# RasbperryPi register map
File version: 1
Registers are 32-bit, read-write, reset 0x0 unless marked. A register's access mark holds for its fields unless they carry their own. Offsets are from the block's base; [hi:lo] are bit positions; {n}, {i} and the like mark numbered series.

## HDMI — Derived from hdmicore.h
Base 0x7E902000
0x00 CORE_REV 16-bit
  [15:0] data
0x00 CEC_TX_DATA_2
  [31:0] data
{0x0+4i} RAM_GCP_{i} (i=0..8)
  [31:0] data
0x00 RAM_PACKET_7_1
  [31:0] data
0x04 SW_RESET_CNTRL 2-bit
  [1:0] data
0x04 CEC_TX_DATA_3
  [31:0] data
0x04 RAM_PACKET_7_2
  [31:0] data
0x08 HOTPLUG_INT 3-bit reset 0x6
  [2:0] data
0x08 CEC_TX_DATA_4
  [31:0] data
0x08 RAM_PACKET_7_3
  [31:0] data
0x0C HOTPLUG 1-bit
  [0] data
{0x8+4i} CEC_RX_DATA_{i} (i=1..4)
  [31:0] data
0x0C RAM_PACKET_7_4
  [31:0] data
0x10 BKSV0
  [31:0] data
0x10 RAM_PACKET_7_5
  [31:0] data
0x14 BKSV1
  [31:0] data
0x14 RAM_PACKET_7_6
  [31:0] data
0x18 AN0
  [31:0] data
0x18 RAM_PACKET_7_7
  [31:0] data
0x1C AN1
  [31:0] data
0x1C PACKET_FIFO_CTL 2-bit
  [1:0] data
0x1C RAM_PACKET_7_8
  [31:0] data
0x20 AN_INFLUENCE_1
  [31:0] data
0x20 PACKET_FIFO_CFG 1-bit
  [0] data
{0x20+4i} RAM_PACKET_8_{i} (i=0..8)
  [31:0] data
0x24 AN_INFLUENCE_2
  [31:0] data
0x24 PACKET_FIFO_STATUS 26-bit
  [25:0] data
{0x24+4i} RAM_PACKET_1_{i} (i=0..8)
  [31:0] data
0x28 TST_AN0
  [31:0] data
0x28 DVO_TIMING_ADJUST_A 20-bit reset 0x88
  [19:0] data
0x2C TST_AN1
  [31:0] data
0x2C DVO_TIMING_ADJUST_B reset 0x88
  [31:0] data
0x30 KSV_FIFO_0
  [31:0] data
0x30 DVO_TIMING_ADJUST_C reset 0x88
  [31:0] data
0x34 KSV_FIFO_1 8-bit
  [7:0] data
0x34 DVO_TIMING_ADJUST_D reset 0x88
  [31:0] data
0x38 V
  [31:0] data
0x38 DETECTED_HORZA 15-bit reset 0x80
  [14] MANUAL_VPOL, [13] MANUAL_HPOL, [12:0] MANUAL_HAP
0x3C HDCP_KEY_1
  [31:0] data
0x3C DETECTED_HORZB 30-bit reset 0x10
  [29:20] MANUAL_HBP, [19:10] MANUAL_HSP, [9] MANUAL_HFP, [8:0] _
0x40 HDCP_KEY_2
  [31:0] data
0x40 DETECTED_VERTA0 25-bit reset 0xE0
  [24:20] MANUAL_VSP0, [19:13] MANUAL_VFP0, [12:0] MANUAL_VAL0
0x40 CPU_STATUS
  [31:0] data
0x44 HDCP_CTL 17-bit
  [16:0] data
0x44 DETECTED_VERTB0 22-bit reset 0x21
  [21:9] MANUAL_VSPO0, [8] MANUAL_VBP0, [7:0] _
0x44 CPU_SET
  [31:0] data
{0x44+4i} RAM_PACKET_9_{i} (i=0..8)
  [31:0] data
0x48 CP_STATUS
  [31:0] data
0x48 DETECTED_VERTA1 25-bit reset 0xE0
  [24:20] MANUAL_VSP1, [19:13] MANUAL_VFP1, [12:0] MANUAL_VAL1
0x48 CPU_CLEAR
  [31:0] data
{0x48+4i} RAM_PACKET_2_{i} (i=0..8)
  [31:0] data
0x4C CP_INTEGRITY
  [31:0] data
0x4C DETECTED_VERTB1 22-bit reset 0x21
  [21:9] MANUAL_VSPO1, [8] MANUAL_VBP1, [7:0] _
0x4C CPU_MASK_STATUS reset 0xFF
  [31:0] data
0x50 CP_INTEGRITY_CFG 17-bit
  [16:0] data
0x50 13_AUDIO_CFG_1 10-bit reset 0xC8
  [9:0] data
0x50 CPU_MASK_SET reset 0xFF
  [31:0] data
0x54 CP_CONFIG 31-bit reset 0x80
  [30:0] data
0x54 13_AUDIO_STATUS_1 1-bit
  [0] data
0x54 CPU_MASK_CLEAR reset 0xFF
  [31:0] data
0x58 CP_TST 22-bit
  [21:0] data
0x58 HBR_AUDIO_PACKET_HEADER 20-bit reset 0x9
  [19:0] data
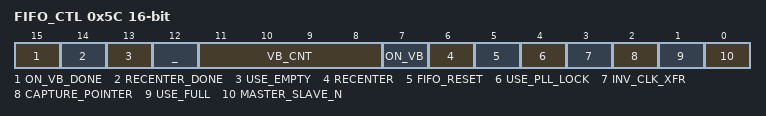
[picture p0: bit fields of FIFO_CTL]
0x5C FIFO_CTL 16-bit
  [15] ON_VB_DONE, [14] RECENTER_DONE, [13] USE_EMPTY, [12] _, [11:8] VB_CNT, [7] ON_VB, [6] RECENTER, [5] FIFO_RESET, [4] USE_PLL_LOCK, [3] INV_CLK_XFR, [2] CAPTURE_POINTER, [1] USE_FULL, [0] MASTER_SLAVE_N
0x5C POSTING_MASTER 8-bit reset 0xFF
  [7:0] data
0x60 READ_POINTERS 31-bit
  [30] DOMAIN_HALF_FULL, [29:27] DOMAIN_WR_ADDR, [26:24] DOMAIN_RESYNC_RD, [23] DRFT_HOLD_WR, [22] DRFT_HOLD_RD, [21] DRFT_ALMOST_FULL, [20] DRFT_FULL_MINUS, [19] DRFT_OVERFLOW, [18] DRFT_ALMOST_MT, [17] DRFT_EMPTY_MINUS, [16] DRFT_UNDERFLOW, [15:8] DRFT_WR_ADDR, [7] DRFT_RD_ADDR, [6:0] _
{0x68+4i} RAM_PACKET_10_{i} (i=0..8)
  [31:0] data
{0x6C+4i} RAM_PACKET_3_{i} (i=0..8)
  [31:0] data
0x70 ENCODER_CTL 1-bit
  [0] data
0x74 PERT_CONFIG 12-bit
  [11:0] data
0x78 PERT_LFSR_PRELOAD
  [31:0] data
0x7C PERT_LFSR_FEEDBACK_MASK
  [31:0] data
0x80 PERT_INSERT_ERR 24-bit
  [23:0] data
0x84 PERT_INSERT_ERR_SEP
  [31:0] data
0x88 PERT_TEST_LENGTH
  [31:0] data
0x8C PERT_DATA 24-bit
{0x8C+4i} RAM_PACKET_11_{i} (i=0..8)
  [31:0] data
0x90 MAI_CHANNEL_MAP 24-bit reset 0x88
  [23:0] data
{0x90+4i} RAM_PACKET_4_{i} (i=0..8)
  [31:0] data
0x94 MAI_CONFIG 28-bit reset 0x3
  [27:0] data
0x98 MAI_FORMAT
  [31:0] data
0x9C AUDIO_PACKET_CONFIG 30-bit reset 0x3
  [29:0] data
0xA0 RAM_PACKET_CONFIG 17-bit
  [16:0] data
0xA4 RAM_PACKET_STATUS 14-bit
  [13:0] data
0xA8 CRP_CFG 28-bit
  [27:0] data
0xAC CTS_0 20-bit
  [19:0] data
0xB0 CTS_1 20-bit
  [19:0] data
{0xB0+4i} RAM_PACKET_12_{i} (i=0..8)
  [31:0] data
0xB4 CTS_PERIOD_0 reset 0xF8
  [31:0] data
{0xB4+4i} RAM_PACKET_5_{i} (i=0..8)
  [31:0] data
0xB8 CTS_PERIOD_1 reset 0xF8
  [31:0] data
0xBC BCH_CONFIGURATION 9-bit reset 0x83
  [8:0] data
0xC0 SCHEDULER_CONTROL 22-bit reset 0x8
  [21:18] VSYNC_RESET_VAL, [17] VSYNC_PHYST_EN, [16] HSYNC_PHYST_EN, [15] MANUAL_FORMAT, [14] USE_POSTLN_AVOID, [13:8] POSTLN_AVOID, [7] _, [6] ENC_ONLY_WHEN_AUTH, [5] IGN_VSYNC_PREDS, [4] ALWS_REKEY_KEEPOUT, [3] ALWS_VERT_KEEPOUT, [2] USE_PREDICTS, [1] MODE_ACTIVE, [0] MODE_REQ
0xC0 TX_PHY_TX_PHY_RESET_CTL reset 0xFF
  [31:0] data
0xC4 HORZA 15-bit reset 0x80
  [14] MANUAL_VPOL, [13] MANUAL_HPOL, [12:0] MANUAL_HAP
0xC4 TX_PHY_TX_PHY_CTL_0
  [31:0] data
0xC8 HORZB 30-bit reset 0x10
  [29:20] MANUAL_HBP, [19:10] MANUAL_HSP, [9] MANUAL_HFP, [8:0] _
0xC8 TX_PHY_TX_PHY_CTL_1 reset 0x8
  [31:0] data
0xCC VERTA0 25-bit reset 0xE0
  [24:20] MANUAL_VSP0, [19:13] MANUAL_VFP0, [12:0] MANUAL_VAL0
0xCC TX_PHY_TX_PHY_CTL_2 reset 0x4
  [31:0] data
0xD0 VERTB0 22-bit reset 0x21
  [21:9] MANUAL_VSPO0, [8] MANUAL_VBP0, [7:0] _
0xD0 TX_PHY_TX_PHY_PLL_CFG reset 0x12
  [31:0] data
0xD4 VERTA1 25-bit reset 0xE0
  [24:20] MANUAL_VSP1, [19:13] MANUAL_VFP1, [12:0] MANUAL_VAL1
0xD4 TX_PHY_TX_PHY_TMDS_CFG reset 0x1F
  [31:0] data
{0xD4+4i} RAM_PACKET_13_{i} (i=0..8)
  [31:0] data
0xD8 VERTB1 22-bit reset 0x21
  [21:9] MANUAL_VSPO1, [8] MANUAL_VBP1, [7:0] _
0xD8 TX_PHY_TX_PHY_STATUS
  [31:0] data
{0xD8+4i} RAM_PACKET_6_{i} (i=0..8)
  [31:0] data
0xDC TEST 12-bit
  [11:0] data
0xDC TX_PHY_SPREAD_SPECTRUM
  [31:0] data
0xE0 MBIST_TM 24-bit
  [23:0] data
0xE0 TX_PHY_TX_PHY_SPARE
  [31:0] data
0xE4 MISC_CONTROL 31-bit
  [30:0] data
0xE8 CEC_CNTRL_1 reset 0xBE
  [31:0] data
0xEC CEC_CNTRL_2 31-bit reset 0xD5
  [30:0] data
0xF0 CEC_CNTRL_3 reset 0x5C
  [31:0] data
0xF4 CEC_CNTRL_4 reset 0xBE
  [31:0] data
0xF8 CEC_CNTRL_5 28-bit reset 0xF5
  [27:0] data
0xFC CEC_TX_DATA_1
  [31:0] data
0xFC RAM_PACKET_7_0
  [31:0] data
